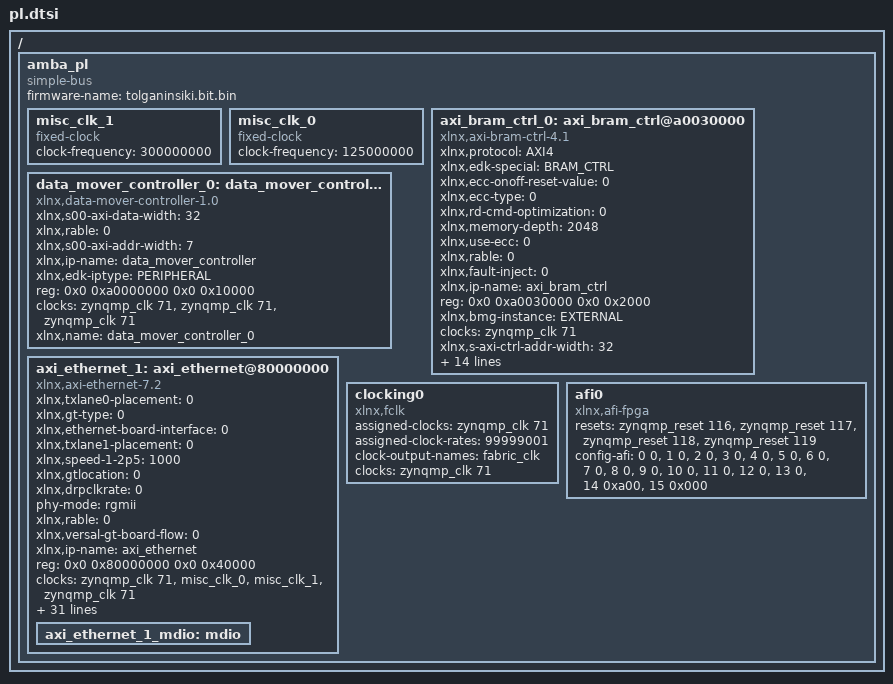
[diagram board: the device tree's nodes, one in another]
/ {
	amba_pl: amba_pl {
		ranges;
		compatible = "simple-bus";
		#address-cells = <2>;
		#size-cells = <2>;
		firmware-name = "tolganinsiki.bit.bin";
		misc_clk_1: misc_clk_1 {
			compatible = "fixed-clock";
			clock-frequency = <300000000>;
			#clock-cells = <0>;
		};
		misc_clk_0: misc_clk_0 {
			compatible = "fixed-clock";
			clock-frequency = <125000000>;
			#clock-cells = <0>;
		};
		axi_bram_ctrl_0: axi_bram_ctrl@a0030000 {
			xlnx,protocol = "AXI4";
			xlnx,edk-special = "BRAM_CTRL";
			compatible = "xlnx,axi-bram-ctrl-4.1";
			xlnx,ecc-onoff-reset-value = <0>;
			xlnx,ecc-type = <0>;
			xlnx,rd-cmd-optimization = <0>;
			xlnx,memory-depth = <2048>;
			xlnx,use-ecc = <0>;
			xlnx,rable = <0>;
			xlnx,fault-inject = <0>;
			xlnx,ip-name = "axi_bram_ctrl";
			reg = <0x0 0xa0030000 0x0 0x2000>;
			xlnx,bmg-instance = "EXTERNAL";
			clocks = <&zynqmp_clk 71>;
			xlnx,s-axi-ctrl-addr-width = <32>;
			xlnx,read-latency = <1>;
			xlnx,s-axi-supports-narrow-burst = <0>;
			xlnx,id-width = <0>;
			xlnx,supports-narrow-burst = <0>;
			xlnx,single-port-bram = <1>;
			xlnx,ecc = <0>;
			xlnx,edk-iptype = "PERIPHERAL";
			status = "okay";
			clock-names = "s_axi_aclk";
			xlnx,bram-addr-width = <11>;
			xlnx,bram-inst-mode = "EXTERNAL";
			xlnx,data-width = <32>;
			xlnx,s-axi-ctrl-data-width = <32>;
			xlnx,s-axi-id-width = <1>;
			xlnx,mem-depth = <2048>;
			xlnx,name = "axi_bram_ctrl_0";
		};
		data_mover_controller_0: data_mover_controller@a0000000 {
			xlnx,s00-axi-data-width = <32>;
			xlnx,rable = <0>;
			compatible = "xlnx,data-mover-controller-1.0";
			status = "okay";
			clock-names = "m00_axis_aclk" , "s00_axi_aclk" , "s00_axis_aclk";
			xlnx,s00-axi-addr-width = <7>;
			xlnx,ip-name = "data_mover_controller";
			xlnx,edk-iptype = "PERIPHERAL";
			reg = <0x0 0xa0000000 0x0 0x10000>;
			clocks = <&zynqmp_clk 71>, <&zynqmp_clk 71>, <&zynqmp_clk 71>;
			xlnx,name = "data_mover_controller_0";
		};
		axi_ethernet_1: axi_ethernet@80000000 {
			xlnx,txlane0-placement = "0";
			xlnx,gt-type = "0";
			compatible = "xlnx,axi-ethernet-7.2" , "xlnx,axi-ethernet-1.00.a" , "xlnx,axi-ethernet-1.00.a";
			xlnx,ethernet-board-interface = "0";
			xlnx,txlane1-placement = "0";
			xlnx,speed-1-2p5 = <1000>;
			xlnx,gtlocation = "0";
			xlnx,drpclkrate = <0>;
			phy-mode = "rgmii";
			xlnx,rable = <0>;
			xlnx,versal-gt-board-flow = <0>;
			xlnx,ip-name = "axi_ethernet";
			reg = <0x0 0x80000000 0x0 0x40000>;
			clocks = <&zynqmp_clk 71>, <&misc_clk_0>, <&misc_clk_1>, <&zynqmp_clk 71>;
			xlnx,rxmem = <0x1000>;
			xlnx,include-io;
			xlnx,tx-in-upper-nibble;
			xlnx,rxcsum = <0x0>;
			xlnx,processor-mode;
			xlnx,gtrefclksrc = "0";
			xlnx,clockselection = "0";
			xlnx,txmem = "0";
			xlnx,statistics-counters;
			xlnx,axisclkrate = <0>;
			xlnx,txcsum = <0x0>;
			xlnx,phyaddr = <0x1>;
			xlnx,mdio-board-interface = "0";
			xlnx,edk-iptype = "0";
			xlnx,supportlevel = <0>;
			xlnx,phyrst-board-interface = "0";
			local-mac-address = [ 00 0a 23 00 00 00 ];
			xlnx,gtrefclkrate = <0>;
			xlnx,frame-filter;
			status = "okay";
			xlnx,axiliteclkrate = <0>;
			xlnx,diffclk-board-interface = "0";
			clock-names = "axis_clk" , "gtx_clk" , "ref_clk" , "s_axi_lite_clk";
			xlnx,use-board-flow;
			xlnx,timer-format = <0>;
			xlnx,number-of-table-entries = <0>;
			xlnx,lvdsclkrate = <0>;
			xlnx,timer-clk-period = <0>;
			xlnx,statistics-width = "0";
			xlnx,rxlane0-placement = "0";
			xlnx,phyrst-board-interface-dummy-port = "0";
			xlnx,rxlane1-placement = "0";
			xlnx,name = "axi_ethernet_1";
			axi_ethernet_1_mdio: mdio {
				#address-cells = <1>;
				#size-cells = <0>;
			};
		};
		clocking0: clocking0 {
			compatible = "xlnx,fclk";
			assigned-clocks = <&zynqmp_clk 71>;
			assigned-clock-rates = <99999001>;
			#clock-cells = <0>;
			clock-output-names = "fabric_clk";
			clocks = <&zynqmp_clk 71>;
		};
		afi0: afi0 {
			status = "okay";
			compatible = "xlnx,afi-fpga";
			resets = <&zynqmp_reset 116>, <&zynqmp_reset 117>, <&zynqmp_reset 118>, <&zynqmp_reset 119>;
			config-afi = < 0 0>, <1 0>, <2 0>, <3 0>, <4 0>, <5 0>, <6 0>, <7 0>, <8 0>, <9 0>, <10 0>, <11 0>, <12 0>, <13 0>, <14 0xa00>, <15 0x000>;
		};
	};
};
